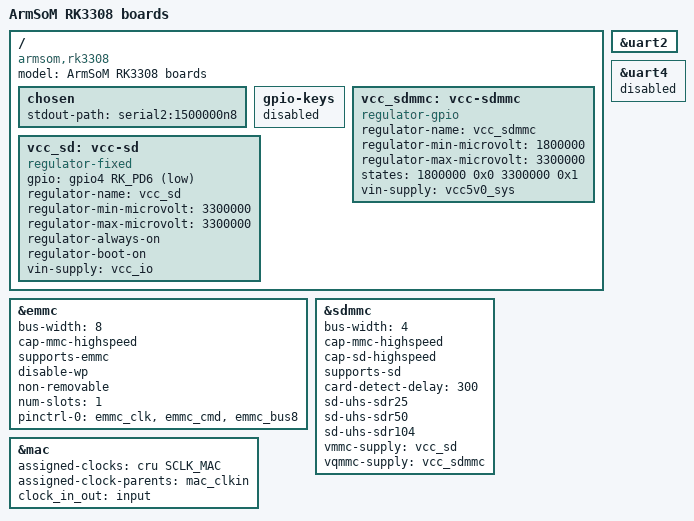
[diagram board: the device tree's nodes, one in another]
/dts-v1/;
#include "rk3308-evb.dts"

/ {
	model = "ArmSoM RK3308 boards";
	compatible = "armsom,rk3308", "rockchip,rk3308";

	chosen {
		stdout-path = "serial2:1500000n8";
	};

	gpio-keys {
		status = "disabled";
	};

	vcc_sdmmc: vcc-sdmmc {
		compatible = "regulator-gpio";
		regulator-name = "vcc_sdmmc";
		regulator-min-microvolt = <1800000>;
		regulator-max-microvolt = <3300000>;
		// gpios = <&gpio0 RK_PA7 GPIO_ACTIVE_HIGH>;
		states = <1800000 0x0
			  3300000 0x1>;
		vin-supply = <&vcc5v0_sys>;
	};

	vcc_sd: vcc-sd {
		compatible = "regulator-fixed";
		gpio = <&gpio4 RK_PD6 GPIO_ACTIVE_LOW>;
		regulator-name = "vcc_sd";
		regulator-min-microvolt = <3300000>;
		regulator-max-microvolt = <3300000>;
		regulator-always-on;
		regulator-boot-on;
		vin-supply = <&vcc_io>;
	};
};

&uart2 {
	status = "okay";
};

&uart4 {
	status = "disabled";
};

&emmc {
	bus-width = <8>;
	cap-mmc-highspeed;
	supports-emmc;
	disable-wp;
	non-removable;
	num-slots = <1>;
	pinctrl-names = "default";
	pinctrl-0 = <&emmc_clk &emmc_cmd &emmc_bus8>;
	status = "okay";
};

&sdmmc {
	bus-width = <4>;
	cap-mmc-highspeed;
	cap-sd-highspeed;
	supports-sd;
	card-detect-delay = <300>;
	sd-uhs-sdr25;
	sd-uhs-sdr50;
	sd-uhs-sdr104;
	vmmc-supply = <&vcc_sd>;
	vqmmc-supply = <&vcc_sdmmc>;
	status = "okay";
};

&mac {
	assigned-clocks = <&cru SCLK_MAC>;
	assigned-clock-parents = <&mac_clkin>;
	clock_in_out = "input";
	status = "okay";
};
